# EFR32BG27C320F768IJ39 register map
Vendor: Silicon Labs; Series: EFR32; File version: B
Registers are 32-bit, read-write, reset 0x0 unless marked. A register's access mark holds for its fields unless they carry their own. Offsets are from the block's base; [hi:lo] are bit positions; {n}, {i} and the like mark numbered series.

## SYSCFG_NS — SYSCFG_NS Registers
Base 0x5007C000
Same registers: SYSCFG_S 0x4007C000
0x00 IPVERSION ro reset 0x5
  [31:0] IPVERSION — New BitField
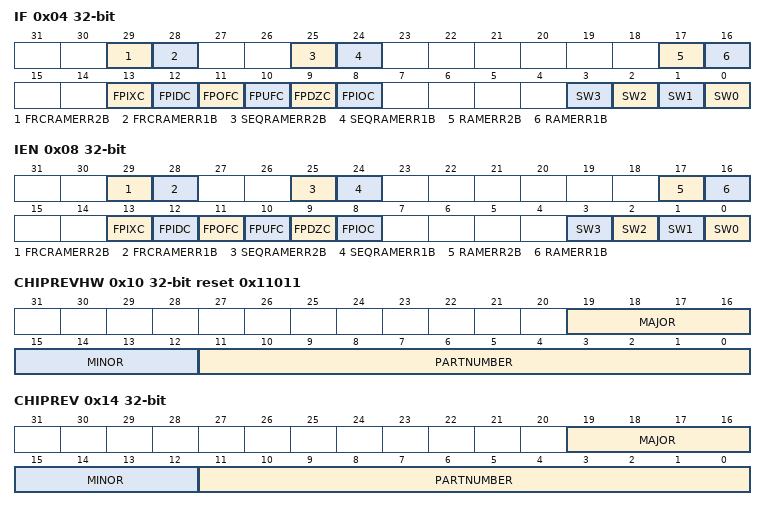
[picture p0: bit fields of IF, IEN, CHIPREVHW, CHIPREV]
0x04 IF — Read to get system status.
  [29] FRCRAMERR2B — FRCRAM Error 2-Bit Interrupt Flag
  [28] FRCRAMERR1B — FRCRAM Error 1-Bit Interrupt Flag
  [25] SEQRAMERR2B — SEQRAM Error 2-Bit Interrupt Flag
  [24] SEQRAMERR1B — SEQRAM Error 1-Bit Interrupt Flag
  [17] RAMERR2B — RAM Error 2-Bit Interrupt Flag
  [16] RAMERR1B — RAM Error 1-Bit Interrupt Flag
  [13] FPIXC — FPU Inexact interrupt flag
  [12] FPIDC — FPU Input denormal interrupt flag
  [11] FPOFC — FPU Overflow interrupt flag
  [10] FPUFC — FPU Underflow interrupt flag
  [9] FPDZC — FPU Divide by zero interrupt flag
  [8] FPIOC — FPU Invalid Operation interrupt flag
  [n] SW{n} (n=0..3) — Software Interrupt Flag
0x08 IEN — Write to enable interrupts.
  [29] FRCRAMERR2B — FRCRAM Error 2-bit Interrupt Enable
  [28] FRCRAMERR1B — FRCRAM Error 1-bit Interrupt Enable
  [25] SEQRAMERR2B — SEQRAM Error 2-bit Interrupt Enable
  [24] SEQRAMERR1B — SEQRAM Error 1-bit Interrupt Enable
  [17] RAMERR2B — RAM Error 2-bit Interrupt Enable
  [16] RAMERR1B — RAM Error 1-bit Interrupt Enable
  [13] FPIXC — FPU Inexact Interrupt Enable
  [12] FPIDC — FPU Input denormal Interrupt Enable
  [11] FPOFC — FPU Overflow Interrupt Enable
  [10] FPUFC — FPU Underflow Interrupt Enable
  [9] FPDZC — FPU Divide by zero Interrupt Enable
  [8] FPIOC — FPU Invalid Operation Interrupt Enable
  [n] SW{n} (n=0..3) — Software Interrupt Enable
0x10 CHIPREVHW reset 0x11011 — Read to get the hard-wired chip revision.
  [19:16] MAJOR ro — Hardwired Chip Major value
  [15:12] MINOR ro — Hardwired Chip Minor value
  [11:0] PARTNUMBER — Hardwired Chip Part Number value
0x14 CHIPREV — Read to get the chip revision programmed by feature configuration.
  [19:16] MAJOR — Chip Revision Major value
  [15:12] MINOR — Chip Revision Minor value
  [11:0] PARTNUMBER — Chip Part Number value
0x20 CFGSYSTIC — Configure the source of the system tick for the M33.
  [0] SYSTICEXTCLKEN — SysTick External Clock Enable
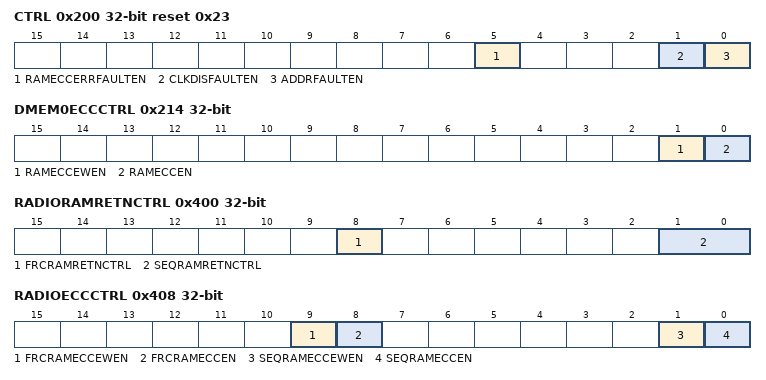
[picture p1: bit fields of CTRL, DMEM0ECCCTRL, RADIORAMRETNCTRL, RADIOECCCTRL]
0x200 CTRL reset 0x23 — Configure to provide general RAM configuration.
  [5] RAMECCERRFAULTEN — Two bit ECC error bus fault response ena
  [1] CLKDISFAULTEN — Disabled Clkbus Bus Fault Enable
  [0] ADDRFAULTEN — Invalid Address Bus Fault Response Enabl
0x208 DMEM0RETNCTRL — Configure to provide general RAM retention configuration.
  [2:0] RAMRETNCTRL — DMEM0 blockset retention control
    0=ALLON (None of the RAM blocks powered down); 1=BLK0 (Power down RAM block 0); 2=BLK1 (Power down RAM block 1); 3=BLK0TO1 (Power down RAM block 0 and 1); 4=BLK2 (Power down RAM block 2); 5=BLK0AND2 (Power down RAM block 0 and 2); 6=BLK1TO2 (Power down RAM block 1 and 2); 7=BLK0TO2 (Power down RAM block 0 and 1)
0x210 DMEM0ECCADDR ro — Read to get status of the DMEM0 ECC error address.
  [31:0] DMEM0ECCADDR — DMEM0 RAM ECC Error Address
0x214 DMEM0ECCCTRL — Configure to set RAM ECC control.
  [1] RAMECCEWEN — RAM ECC Error Writeback Enable
  [0] RAMECCEN — RAM ECC Enable
0x30C RAMBIASCONF reset 0x2 — Configure RAM bias configure bits.
  [3:0] RAMBIASCTRL — RAM Bias Control
    0=No (None); 1=VSB100 (Voltage Source Bias 100mV); 2=VSB200 (Voltage Source Bias 200mV); 4=VSB300 (Voltage Source Bias 300mV); 8=VSB400 (Voltage Source Bias 400mV)
0x400 RADIORAMRETNCTRL — Configure SEQRAM Retention controls.
  [8] FRCRAMRETNCTRL — FRCRAM Retention Control
    0=ALLON (FRCRAM not powered down); 1=ALLOFF (Power down FRCRAM)
  [1:0] SEQRAMRETNCTRL — SEQRAM Retention Control
    0=ALLON (SEQRAM not powered down); 1=BLK0 (Power down SEQRAM block 0); 2=BLK1 (Power down SEQRAM block 1); 3=ALLOFF (Power down all SEQRAM blocks)
0x408 RADIOECCCTRL — Configure to set RAM ECC control.
  [9] FRCRAMECCEWEN — FRCRAM ECC Error Writeback Enable
  [8] FRCRAMECCEN — FRCRAM ECC Enable
  [1] SEQRAMECCEWEN — SEQRAM ECC Error Writeback Enable
  [0] SEQRAMECCEN — SEQRAM ECC Enable
0x410 SEQRAMECCADDR ro — Read to get status of the SEQRAM ECC error address.
  [31:0] SEQRAMECCADDR — SEQRAM ECC Address
0x414 FRCRAMECCADDR ro — Read to get status of the FRCRAM ECC error address.
  [31:0] FRCRAMECCADDR — FRCRAM ECC Error Address
0x418 ICACHERAMRETNCTRL — Configure Host ICACHERAM retention configuration.
  [0] RAMRETNCTRL — ICACHERAM Retention control
    0=ALLON (None of the Host ICACHE RAM blocks powered down); 1=ALLOFF (Power down all Host ICACHE RAM blocks)
0x600 ROOTDATA0 — Generic data space for user to pass to root, e.g., address of struct in mem
  [31:0] DATA
0x604 ROOTDATA1 — Generic data space for user to pass to root, e.g., address of struct in mem
  [31:0] DATA
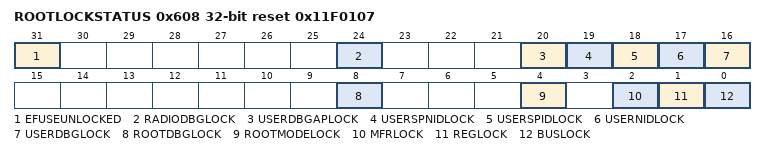
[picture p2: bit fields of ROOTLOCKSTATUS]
0x608 ROOTLOCKSTATUS ro reset 0x11F0107 — This register returns the status of the SE managed locks.
  [31] EFUSEUNLOCKED
  [24] RADIODBGLOCK — Radio Debug Lock
  [20] USERDBGAPLOCK — User Debug Access Port Lock
  [19] USERSPNIDLOCK — User Secure Non-invasive Debug Lock
  [18] USERSPIDLOCK — User Secure Invasive Debug Lock
  [17] USERNIDLOCK — User Non-invasive Debug Lock
  [16] USERDBGLOCK — User Invasive Debug Lock
  [8] ROOTDBGLOCK — Root Debug Lock
  [4] ROOTMODELOCK
  [2] MFRLOCK — Manufacture Lock
  [1] REGLOCK — Register Lock
  [0] BUSLOCK
0x60C ROOTSESWVERSION — SE Software version
  [31:0] SWVERSION
